# CY8C3246PVI_147 register map
File version: 0.1
CY8C32
Registers are 8-bit, read-write, no defined reset value unless marked. A register's access mark holds for its fields unless they carry their own. Offsets are from the block's base; lines under a group give offsets from that group; [hi:lo] are bit positions; {n}, {i} and the like mark numbered series; 'fields as' and 'values as' point back to an identical list; <NAME> marks a mode.

## Memory map
0x00000000 Band_Control
0x00000000 CW_Hold_Control
0x00000000 CW_Hold_Timer
0x00000000 I2S
0x00000000 I2C_DISPLAY
0x00000000 USBFS
0x00000000 USBFS_EP17_DMA_Done_SR
0x00000000 USBFS_EP8_DMA_Done_SR
0x00000000 Control
0x00000000 Status

## Band_Control
Base 0x00000000
0x6576 Band_Control_CONTROL_REG

## CW_Hold_Control
Base 0x00000000
0x6477 CW_Hold_Control_CONTROL_REG

## CW_Hold_Timer
Base 0x00000000
0x43A3 CW_Hold_Timer_GLOBAL_ENABLE — PM.ACT.CFG
  [3:0] en_timer — Enable timer/counters.
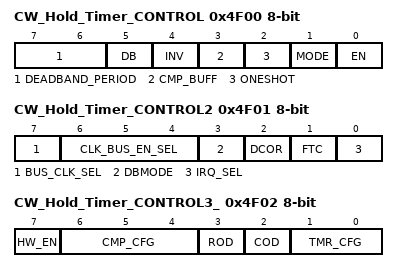
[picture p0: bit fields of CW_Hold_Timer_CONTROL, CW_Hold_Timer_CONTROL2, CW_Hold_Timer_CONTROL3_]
0x4F00 CW_Hold_Timer_CONTROL — TMRx.CFG0
  [7:6] DEADBAND_PERIOD
  [5] DB — Deadband mode--Deadband phases phi1 and phi2 are outputted on CMP and TC output pins respectively.
    0=Timer (CMP and TC are output.); 1=Deadband (PHI1 (instead of CMP) and PHI2 (instead of TC) are output.)
  [4] INV — Invert sense of TIMEREN signal
  [3] CMP_BUFF — Buffer compare register. Compare register updates only on timer terminal count.
  [2] ONESHOT — Timer stops upon reaching stop condition defined by TMR_CFG bits. Can be restarted by asserting TIMER RESET or disabling and re-enabling block.
  [1] MODE — Mode. (0 = Timer; 1 = Comparator)
    0=Timer mode. CNT/CMP register holds timer count value.; 1=Comparator mode. CNT/CMP register holds comparator threshold value.
  [0] EN — Enables timer/comparator.
0x4F01 CW_Hold_Timer_CONTROL2 — TMRx.CFG1
  [7] BUS_CLK_SEL — Bus Clock selection.
  [6:4] CLK_BUS_EN_SEL — Digital Global Clock selection.
  [3] DBMODE — Deadband mode (asynchronous/synchronous). CMP output pin is also affected when not in deadband mode (CFG0.DEADBAND).
  [2] DCOR — Disable Clear on Read (DCOR) of Status Register SR0.
  [1] FTC — First Terminal Count (FTC). Setting this bit forces a single pulse on the TC pin when first enabled.
    0=Disable_FTC (Disable the single cycle pulse, which signifies the timer is starting.); 1=Enable_FTC (Enable the single cycle pulse, which signifies the timer is starting.)
  [0] IRQ_SEL — Irq selection. (0 = raw interrupts; 1 = status register interrupts)
0x4F02 CW_Hold_Timer_CONTROL3_ — TMRx.CFG2
  [7] HW_EN — When set Timer Enable controls counting.
  [6:4] CMP_CFG — Comparator configurations
    0=Equal (Compare Equal); 1=Less_than (Compare Less Than); 2=Less_than_or_equal (Compare Less Than or Equal .); 3=Greater (Compare Greater Than .); 4=Greater_than_or_equal (Compare Greater Than or Equal)
  [3] ROD — Reset On Disable (ROD). Resets internal state of output logic
  [2] COD — Clear On Disable (COD). Clears or gates outputs to zero.
  [1:0] TMR_CFG — Timer configuration (MODE = 0): 000 = Continuous; 001 = Pulsewidth; 010 = Period; 011 = Stop on IRQ
    0=Continuous (Timer runs while EN bit of CFG0 register is set to '1'.); 1=Pulsewidth (Timer runs from positive to negative edge of TIMEREN.); 2=Period (Timer runs from positive to positive edge of TIMEREN.); 3=Irq (Timer runs until IRQ.)
0x4F04 CW_Hold_Timer_PERIOD 16-bit — TMRx.PER0 - Assigned Period
0x4F06 CW_Hold_Timer_COUNTER 16-bit — TMRx.CNT_CMP0 - Current Down Counter Value

## I2S
Base 0x00000000
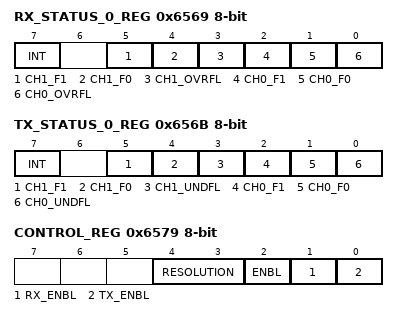
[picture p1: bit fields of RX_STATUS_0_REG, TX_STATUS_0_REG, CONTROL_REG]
0x6569 RX_STATUS_0_REG
  [7] INT ro — Interrupt bit
  [5] CH1_F1 ro — Stereo channel 1 FIFO 1 state
    0=EMPTY; 1=NOT_EMPTY
  [4] CH1_F0 ro — Stereo channel 1 FIFO 0 state
    0=EMPTY; 1=NOT_EMPTY
  [3] CH1_OVRFL ro — Stereo channel 1 FIFO overflow
    0=NO_OVERFLOW; 1=OVERFLOW
  [2] CH0_F1 ro — Stereo channel 0 FIFO 1 state
    0=EMPTY; 1=NOT_EMPTY
  [1] CH0_F0 ro — Stereo channel 0 FIFO 0 state
    0=EMPTY; 1=NOT_EMPTY
  [0] CH0_OVRFL ro — Stereo channel 0 FIFO overflow
    0=NO_OVERFLOW; 1=OVERFLOW
0x656B TX_STATUS_0_REG
  [7] INT ro — Interrupt bit
  [5] CH1_F1 ro — Stereo channel 1 FIFO 1 state
    0=FULL; 1=NOT_FULL
  [4] CH1_F0 ro — Stereo channel 1 FIFO 0 state
    0=FULL; 1=NOT_FULL
  [3] CH1_UNDFL ro — Stereo channel 1 FIFO underflow
    0=NO_UNDERFLOW; 1=UNDERFLOW
  [2] CH0_F1 ro — Stereo channel 0 FIFO 1 state
    0=FULL; 1=NOT_FULL
  [1] CH0_F0 ro — Stereo channel 0 FIFO 0 state
    0=FULL; 1=NOT_FULL
  [0] CH0_UNDFL ro — Stereo channel 0 FIFO underflow
    0=NO_UNDERFLOW; 1=UNDERFLOW
0x6579 CONTROL_REG
  [4:3] RESOLUTION — Specifies data bits value. Applicable only if dynamic bit resolution is selected.
    0=Cy8_BIT; 1=Cy16_BIT; 2=Cy24_BIT; 3=Cy32_BIT
  [2] ENBL — Starts the generation of the WS and SCK outputs.
    1=ENABLED; 0=DISABLED
  [1] RX_ENBL — Enables Rx direction. Applicable only if Rx direction presents for the component.
    1=ENABLED; 0=DISABLED
  [0] TX_ENBL — Enables Tx direction. Applicable only if Tx direction presents for the component.
    1=ENABLED; 0=DISABLED
